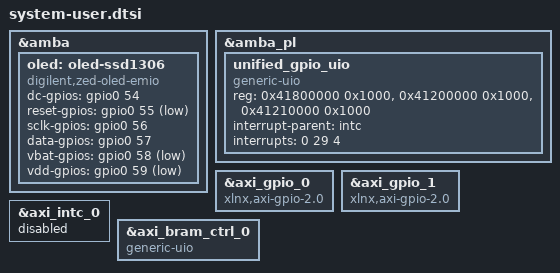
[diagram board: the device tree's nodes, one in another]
#include <dt-bindings/gpio/gpio.h>
#include <dt-bindings/interrupt-controller/irq.h>
/include/ "system-conf.dtsi"

&amba {
    /* ---- Existing OLED over EMIO (unchanged) ---- */
    oled: oled-ssd1306 {
        compatible = "digilent,zed-oled-emio";

        dc-gpios    = <&gpio0 54 GPIO_ACTIVE_HIGH>;
        reset-gpios = <&gpio0 55 GPIO_ACTIVE_LOW>;
        sclk-gpios  = <&gpio0 56 GPIO_ACTIVE_HIGH>;
        data-gpios  = <&gpio0 57 GPIO_ACTIVE_HIGH>;
        vbat-gpios  = <&gpio0 58 GPIO_ACTIVE_LOW>;
        vdd-gpios   = <&gpio0 59 GPIO_ACTIVE_LOW>;

        status = "okay";
    };
};

/* 
 * VISUAL ANCHOR: The Unified Cascaded UIO Controller Node
 * Placed on the amba_pl bus where the peripheral addresses reside.
 */
&amba_pl {
    unified_gpio_uio {
        compatible = "generic-uio";
        status = "okay";

        /* Map 0: Interrupt Controller, Map 1: GPIO 0, Map 2: GPIO 1 */
        /* Note: Address boundaries explicitly match your pl.dtsi space settings */
        reg = <0x41800000 0x1000>,   /* Map 0: axi_intc_0 (4 KB) */
              <0x41200000 0x1000>,   /* Map 1: axi_gpio_0 (4 KB) */
              <0x41210000 0x1000>;   /* Map 2: axi_gpio_1 (4 KB) */

        /* Fixes the missing link back to the primary ARM GIC block */
        interrupt-parent = <&intc>;

        /* 
         * 0 = SPI interrupt type identifier tag.
         * 29 = Hardware interrupt vector slot indexing (29 + 32 = GIC ID 61).
         * 4 = Level-Sensitive Active-High trigger constraint flag.
         */
        interrupts = <0 29 4>; 
    };
};

/* --- Clean out the old standalone profiles to prevent hardware resource tracking leaks --- */

&axi_gpio_0 {
    compatible = "xlnx,axi-gpio-2.0"; 
    /delete-property/ interrupts;     
    /delete-property/ interrupt-parent;
    /delete-property/ interrupt-controller;
};

&axi_gpio_1 {
    compatible = "xlnx,axi-gpio-2.0";
    /delete-property/ interrupts;
    /delete-property/ interrupt-parent;
    /delete-property/ interrupt-controller;
};

/* Override the autogenerated pl.dtsi block so the standalone controller instance does not clash */
&axi_intc_0 {
    status = "disabled"; 
};

/* --- BRAM controller remains independent (no interrupt lines shared) --- */
&axi_bram_ctrl_0 {
    compatible = "generic-uio";
    status = "okay";
};


